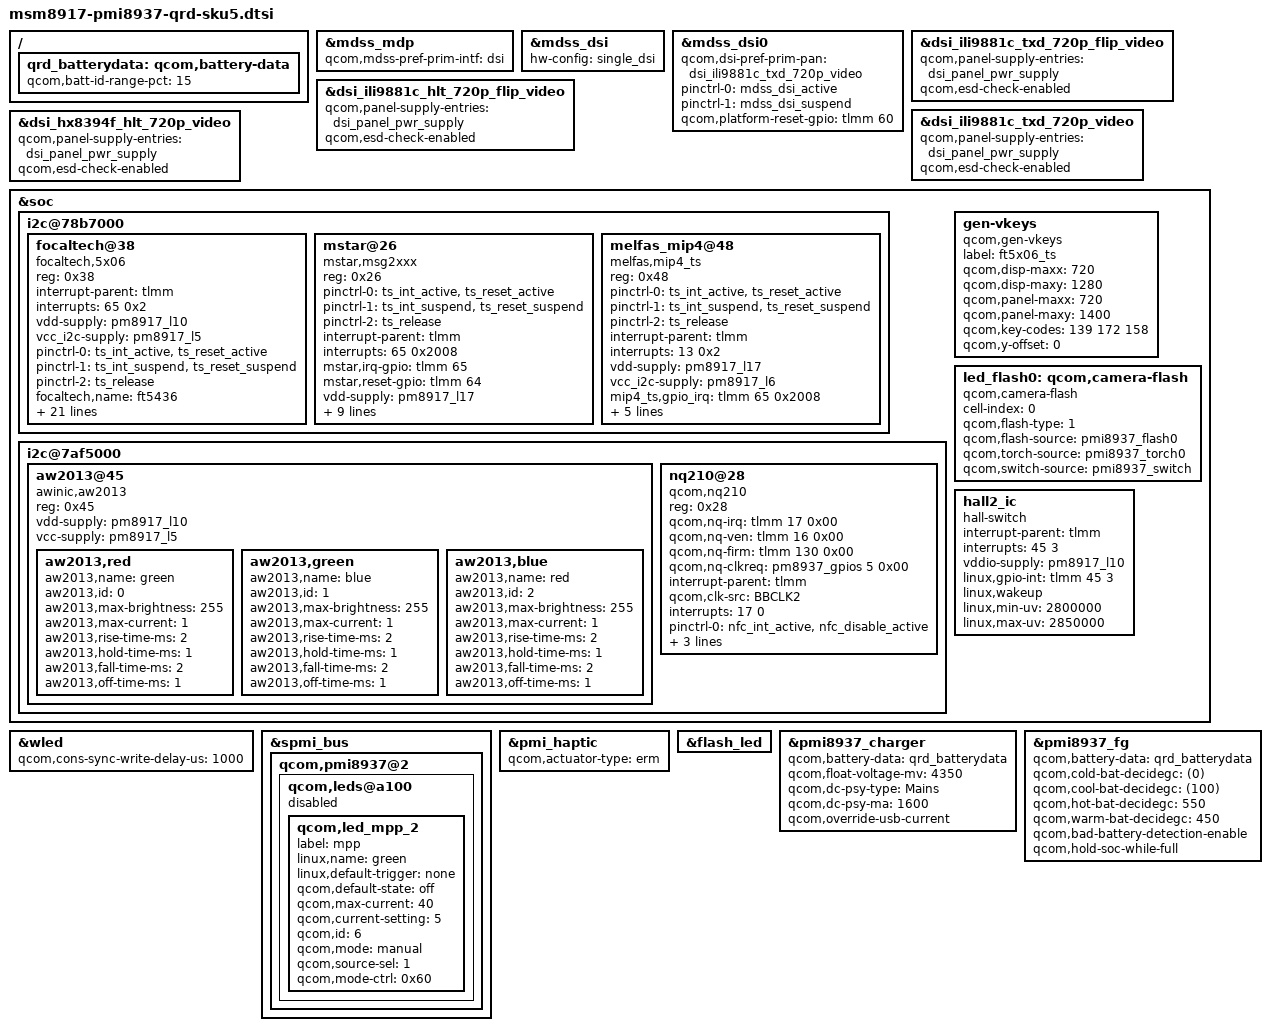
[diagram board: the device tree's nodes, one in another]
/*
 * Copyright (c) 2016, The Linux Foundation. All rights reserved.
 *
 * This program is free software; you can redistribute it and/or modify
 * it under the terms of the GNU General Public License version 2 and
 * only version 2 as published by the Free Software Foundation.
 *
 * This program is distributed in the hope that it will be useful,
 * but WITHOUT ANY WARRANTY; without even the implied warranty of
 * MERCHANTABILITY or FITNESS FOR A PARTICULAR PURPOSE.  See the
 * GNU General Public License for more details.
 */

#include "msm-pmi8937.dtsi"
#include "msm8917-qrd.dtsi"
#include "msm8937-mdss-panels.dtsi"

&mdss_mdp {
	qcom,mdss-pref-prim-intf = "dsi";
};

&mdss_dsi {
	hw-config = "single_dsi";
};

&mdss_dsi0 {
	qcom,dsi-pref-prim-pan = <&dsi_ili9881c_txd_720p_video>;
	pinctrl-names = "mdss_default", "mdss_sleep";
	pinctrl-0 = <&mdss_dsi_active>;
	pinctrl-1 = <&mdss_dsi_suspend>;

	qcom,platform-reset-gpio = <&tlmm 60 0>;
};

&dsi_ili9881c_txd_720p_flip_video {
	qcom,panel-supply-entries = <&dsi_panel_pwr_supply>;
	qcom,esd-check-enabled;
};

&dsi_ili9881c_hlt_720p_flip_video {
	qcom,panel-supply-entries = <&dsi_panel_pwr_supply>;
	qcom,esd-check-enabled;
};

&dsi_ili9881c_txd_720p_video {
	qcom,panel-supply-entries = <&dsi_panel_pwr_supply>;
	qcom,esd-check-enabled;
};

&dsi_hx8394f_hlt_720p_video {
	qcom,panel-supply-entries = <&dsi_panel_pwr_supply>;
	qcom,esd-check-enabled;
};

&soc {
	i2c@78b7000 {
		status = "ok";
		focaltech@38 {
			compatible = "focaltech,5x06";
			reg = <0x38>;
			interrupt-parent = <&tlmm>;
			interrupts = <65 0x2>;
			vdd-supply = <&pm8917_l10>;
			vcc_i2c-supply = <&pm8917_l5>;
			/* pins used by touchscreen */
			pinctrl-names = "pmx_ts_active",
						"pmx_ts_suspend",
						"pmx_ts_release";
			pinctrl-0 = <&ts_int_active &ts_reset_active>;
			pinctrl-1 = <&ts_int_suspend &ts_reset_suspend>;
			pinctrl-2 = <&ts_release>;
			focaltech,name = "ft5436";
			focaltech,family-id = <0x06>;
			focaltech,reset-gpio = <&tlmm 64 0x0>;
			focaltech,irq-gpio = <&tlmm 65 0x2008>;
			focaltech,display-coords = <0 0 720 1280>;
			focaltech,panel-coords = <0 0 720 1400>;
			focaltech,button-map= <139 102 158>;
			focaltech,no-force-update;
			focaltech,i2c-pull-up;
			focaltech,group-id = <1>;
			focaltech,hard-reset-delay-ms = <20>;
			focaltech,soft-reset-delay-ms = <200>;
			focaltech,num-max-touches = <5>;
			focaltech,fw-delay-aa-ms = <30>;
			focaltech,fw-delay-55-ms = <30>;
			focaltech,fw-upgrade-id1 = <0x79>;
			focaltech,fw-upgrade-id2 = <0x08>;
			focaltech,fw-delay-readid-ms = <10>;
			focaltech,fw-delay-era-flsh-ms = <2000>;
			focaltech,fw-auto-cal;
			focaltech,ignore-id-check;
			focaltech,resume-in-workqueue;
		};

		mstar@26 {
			compatible = "mstar,msg2xxx";
			reg = <0x26>;
			pinctrl-names = "pmx_ts_active","pmx_ts_suspend","pmx_ts_release";
			pinctrl-0 = <&ts_int_active &ts_reset_active>;
			pinctrl-1 = <&ts_int_suspend &ts_reset_suspend>;
			pinctrl-2 = <&ts_release>;
			interrupt-parent = <&tlmm>;
			interrupts = <65 0x2008>;
			mstar,irq-gpio = <&tlmm 65 0x2008>;
			mstar,reset-gpio = <&tlmm 64 0x00>;
			vdd-supply = <&pm8917_l17>;
			vcc_i2c-supply = <&pm8917_l6>;
			mstar,name = "msg2xxx";
			mstar,create-vkeys;
			mstar,disp-maxx = <720>;
			mstar,disp-maxy = <1280>;
			mstar,panel-maxx = <720>;
			mstar,panel-maxy = <1380>;
			mstar,key-codes = <158 172 139>;
			mstar,y-offset = <0>;
		};

		melfas_mip4@48 {
			compatible = "melfas,mip4_ts";
			reg = <0x48>;
			pinctrl-names = "pmx_ts_active","pmx_ts_suspend","pmx_ts_release";
			pinctrl-0 = <&ts_int_active &ts_reset_active>;
			pinctrl-1 = <&ts_int_suspend &ts_reset_suspend>;
			pinctrl-2 = <&ts_release>;
			interrupt-parent = <&tlmm>;
			interrupts = <13 0x2>;
			vdd-supply = <&pm8917_l17>;
			vcc_i2c-supply = <&pm8917_l6>;
			mip4_ts,gpio_irq = <&tlmm 65 0x2008>;
			mip4_ts,gpio_reset = <&tlmm 64 0x00>;
			mip4_ts,max_x = <720>;
			mip4_ts,max_y = <1280>;
			melfas,adapter_id = "mip4_ts";
			mip4_ts,create-vkeys;
		};
	};

	i2c@7af5000 {
		status = "ok";
		aw2013@45 {
			compatible = "awinic,aw2013";
			reg = <0x45>;
			vdd-supply = <&pm8917_l10>;
			vcc-supply = <&pm8917_l5>;

			aw2013,red {
				aw2013,name = "green";
				aw2013,id = <0>;
				aw2013,max-brightness = <255>;
				aw2013,max-current = <1>;
				aw2013,rise-time-ms = <2>;
				aw2013,hold-time-ms = <1>;
				aw2013,fall-time-ms = <2>;
				aw2013,off-time-ms = <1>;
			};

			aw2013,green {
				aw2013,name = "blue";
				aw2013,id = <1>;
				aw2013,max-brightness = <255>;
				aw2013,max-current = <1>;
				aw2013,rise-time-ms = <2>;
				aw2013,hold-time-ms = <1>;
				aw2013,fall-time-ms = <2>;
				aw2013,off-time-ms = <1>;
			};

			aw2013,blue {
				aw2013,name = "red";
				aw2013,id = <2>;
				aw2013,max-brightness = <255>;
				aw2013,max-current = <1>;
				aw2013,rise-time-ms = <2>;
				aw2013,hold-time-ms = <1>;
				aw2013,fall-time-ms = <2>;
				aw2013,off-time-ms = <1>;
			};
		};

		nq210@28 {
		compatible = "qcom,nq210";
		reg = <0x28>;
		qcom,nq-irq = <&tlmm 17 0x00>;
		qcom,nq-ven = <&tlmm 16 0x00>;
		qcom,nq-firm = <&tlmm 130 0x00>;
		qcom,nq-clkreq = <&pm8937_gpios 5 0x00>;
		interrupt-parent = <&tlmm>;
		qcom,clk-src = "BBCLK2";
		interrupts = <17 0>;
		interrupt-names = "nfc_irq";
		pinctrl-names = "nfc_active", "nfc_suspend";
		pinctrl-0 = <&nfc_int_active &nfc_disable_active>;
		pinctrl-1 = <&nfc_int_suspend &nfc_disable_suspend>;
		clocks = <&clock_gcc clk_bb_clk2_pin>;
		clock-names = "ref_clk";
		};
	};

	gen-vkeys {
		compatible = "qcom,gen-vkeys";
		label = "ft5x06_ts";
		qcom,disp-maxx = <720>;
		qcom,disp-maxy = <1280>;
		qcom,panel-maxx = <720>;
		qcom,panel-maxy = <1400>;
		qcom,key-codes = <139 172 158>;
		qcom,y-offset = <0>;
	};
};

&wled {
	qcom,cons-sync-write-delay-us = <1000>;
};

&spmi_bus {
	qcom,pmi8937@2 {
		qcom,leds@a100 {
			status = "disabled";
			qcom,led_mpp_2 {
				label = "mpp";
				linux,name = "green";
				linux,default-trigger = "none";
				qcom,default-state = "off";
				qcom,max-current = <40>;
				qcom,current-setting = <5>;
				qcom,id = <6>;
				qcom,mode = "manual";
				qcom,source-sel = <1>;
				qcom,mode-ctrl = <0x60>;
			};
		};
	};
};

&pmi_haptic {
	status = "okay";
	qcom,actuator-type = "erm";
	/delete-property/ qcom,lra-auto-res-mode;
	/delete-property/ qcom,lra-high-z;
	/delete-property/ qcom,lra-res-cal-period;
	/delete-property/ qcom,correct-lra-drive-freq;
	/delete-property/ qcom,misc-trim-error-rc19p2-clk-reg-present;
};

&flash_led {
	/delete-node/ qcom,flash_1;
	/delete-node/ qcom,torch_1;
};

&soc {
	led_flash0: qcom,camera-flash {
		cell-index = <0>;
		compatible = "qcom,camera-flash";
		qcom,flash-type = <1>;
		qcom,flash-source = <&pmi8937_flash0>;
		qcom,torch-source = <&pmi8937_torch0>;
		qcom,switch-source = <&pmi8937_switch>;
	};

	hall2_ic {
		compatible = "hall-switch";
		interrupt-parent = <&tlmm>;
		interrupts = <45 3>;
		interrupt-names = "hall-int";
		vddio-supply = <&pm8917_l10>;
		linux,gpio-int = <&tlmm 45 3>;
		linux,wakeup;
		linux,min-uv = <2800000>;
		linux,max-uv = <2850000>;
	};
};

/ {
	qrd_batterydata: qcom,battery-data {
		qcom,batt-id-range-pct = <15>;
		#include "2314401_CK_M3000A_3000mAh_averaged_MasterSlave_Feb16th2016_PMI8952GUI20015.dtsi"
	};
};

&pmi8937_charger {
	qcom,battery-data = <&qrd_batterydata>;
	qcom,float-voltage-mv = <4350>;
	qcom,dc-psy-type = "Mains";
	qcom,dc-psy-ma = <1600>;
	status = "okay";
	qcom,override-usb-current;
};

&pmi8937_fg {
	qcom,battery-data = <&qrd_batterydata>;
	qcom,cold-bat-decidegc = <(0)>;
	qcom,cool-bat-decidegc = <(100)>;
	qcom,hot-bat-decidegc = <550>;
	qcom,warm-bat-decidegc = <450>;
	qcom,bad-battery-detection-enable;
	qcom,hold-soc-while-full;
};
